# EVTULL register map
Vendor: Texas Instruments
Peripheral module from a debugger description file (folder CC27xxx10).
Registers are 32-bit, access per field, reset values left out (the file's numbers can be read two ways) unless marked. A register's access mark holds for its fields unless they carry their own. Offsets are as the file gives them; lines under a group give offsets from that group; [hi:lo] are bit positions; {n}, {i} and the like mark numbered series; 'fields as' and 'values as' point back to an identical list; <NAME> marks a mode.

## EVTULL — This is top module of Event Fabric for LOKI
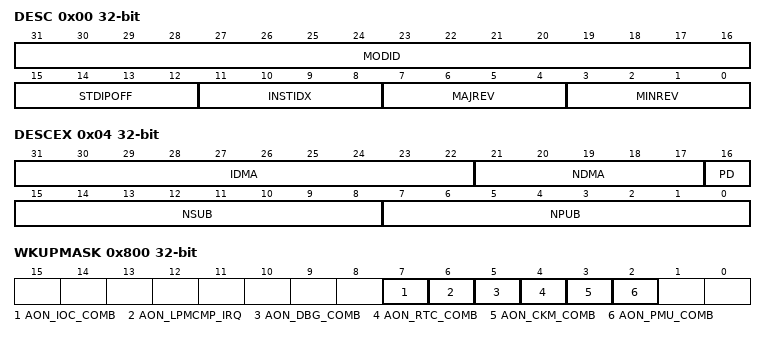
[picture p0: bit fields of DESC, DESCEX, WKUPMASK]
0x00 DESC ro — This register provides IP module ID, revision information, instance index and standard MMR registers offset.
  [31:16] MODID — Module identifier
  [15:12] STDIPOFF — 64 B Standard IP MMR block 0: STDIP MMRs do not exist 1:15: These MMRs begin at offset 64*STDIPOFF from IP base address
  [11:8] INSTIDX — IP Instance number
  [7:4] MAJREV — Major revision
  [3:0] MINREV — Minor revision
0x04 DESCEX ro — Extended Description This register provides configuration details of the IP to software drivers and end users.
  [31:22] IDMA — Nember of DMA input channels
  [21:17] NDMA — Number of DMA output channels
  [16] PD — Power Domain. 0 : SVT 1 : ULL
  [15:8] NSUB — Number of Subscribers
  [7:0] NPUB — Number of Publishers
0x64 DTB — Digital test bus control register This register can be used to bring out IP internal signals to the pads for observation. 16 signals can be observed per select value.
  [0] SEL rw — DTB Selection
0x404 RTCCPTSEL — Output Selection for RTCCPT
  [6:0] PUBID rw — Read/write selection value. Writing any other value than values defined by a ENUM may result in undefined behavior.
    7=AON_IOC_COMB (IOC synchronous combined event, controlled by IOC:EVTCFG); 6=AON_LPMCMP_IRQ (AON LPCMP interrupt, controlled by SYS0:LPCMPCFG); 5=AON_DBG_COMB (DebugSS combined interrupt, interrupt flags can be found here DBGSS:MIS); 4=AON_RTC_COMB (AON_RTC event, controlled by the RTC:IMASK setting); 3=AON_CKM_COMB (CKMD combined interrupt request, interrupt flags can be found here CKMD:MIS); 2=AON_PMU_COMB (PMU combined interrupt request for BATMON, interrupt flags can be found here PMUD:EVENT); 0=NONE (Always inactive)
0x800 WKUPMASK — WAKEUP Mask
  [7] AON_IOC_COMB rw — Wake-up mask for AON_IOC_COMB. 0 - Wakeup Disabled 1 - Wakeup Enabled
  [6] AON_LPMCMP_IRQ rw — Wake-up mask for AON_LPCMP_IRQ. 0 - Wakeup Disabled 1 - Wakeup Enabled
  [5] AON_DBG_COMB rw — Wake-up mask for AON_DBG_COMB. 0 - Wakeup Disabled 1 - Wakeup Enabled
  [4] AON_RTC_COMB rw — Wake-up mask for AON_RTC_COMB. 0 - Wakeup Disabled 1 - Wakeup Enabled
  [3] AON_CKM_COMB rw — Wake-up mask for AON_CKM_COMB. 0 - Wakeup Disabled 1 - Wakeup Enabled
  [2] AON_PMU_COMB rw — Wake-up mask for AON_PMU_COMB. 0 - Wakeup Disabled 1 - Wakeup Enabled
